# NM1330AE_v1 register map
File version: 1.0
Registers are 32-bit, read-write, reset 0x0 unless marked. A register's access mark holds for its fields unless they carry their own. Offsets are from the block's base; [hi:lo] are bit positions; {n}, {i} and the like mark numbered series.

## GCR — GCR Register Map
Base 0x50000000
0x00 PDID ro reset 0x10005200 — Part Device Identification Number Register
  [31:0] PDID — Part Device Identification Number. This register reflects the device part number code. Software can read this register to identify which device is used. For example, M052LBN PDID code is 0x1000_5200.
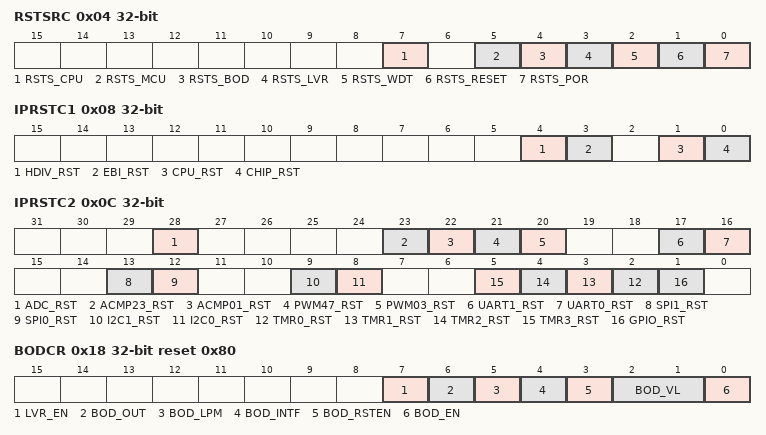
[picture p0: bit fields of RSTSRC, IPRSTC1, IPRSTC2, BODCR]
0x04 RSTSRC (reset mask 0xFFFFFF00) — System Reset Source Register
  [7] RSTS_CPU — CPU Reset Flag. The RSTS_CPU flag is set by hardware if software writes CPU_RST (IPRSTC1[1]) 1 to reset Cortex-M0 core and Flash memory controller (FMC). Note: Write 1 to clear this bit to 0.
    0=No reset from CPU; 1=Cortex-M0 core and FMC are reset by software setting CPU_RST to 1
  [5] RSTS_MCU — MCU Reset Flag. The RSTS_MCU flag is set by the "reset signal" from the Cortex-M0 core to indicate the previous reset source. Note: Write 1 to clear this bit to 0.
    0=No reset from Cortex-M0; 1=The Cortex-M0 had issued the reset signal to reset the system by writing 1 to bit SYSRESETREQ (AIRCR[2], Application Interrupt and Reset Control Register, address = 0xE000ED0C) in system control registers of Cortex-M0 core
  [4] RSTS_BOD — Brown-out Detector Reset Flag. The RSTS_BOD flag is set by the "reset signal" from the Brown-out Detector to indicate the previous reset source. Note: Write 1 to clear this bit to 0.
    0=No reset from BOD; 1=The BOD had issued the reset signal to reset the system
  [3] RSTS_LVR — Low Voltage Reset Flag. The RSTS_LVR flag is set by the "reset signal" from the Low-Voltage-Reset controller to indicate the previous reset source. Note: Write 1 to clear this bit to 0.
    0=No reset from LVR; 1=The LVR controller had issued the reset signal to reset the system
  [2] RSTS_WDT — Watchdog Reset Flag. The RSTS_WDT flag is set by the "reset signal" from the watchdog timer to indicate the previous reset source. Note: Write 1 to clear this bit to 0.
    0=No reset from watchdog timer; 1=The watchdog timer had issued the reset signal to reset the system
  [1] RSTS_RESET — Reset Pin Reset Flag. The RSTS_RESET flag is set by the "reset signal" from the nRST pin to indicate the previous reset source. Note: Write 1 to clear this bit to 0.
    0=No reset from the nRST pin; 1=The nRST pin had issued the reset signal to reset the system
  [0] RSTS_POR — Power-on Reset Flag. The RSTS_POR flag is set by the "reset signal" from the Power-on Reset (POR) controller or bit CHIP_RST (IPRSTC1[0]) to indicate the previous reset source. Note: Write 1 to clear this bit to 0.
    0=No reset from POR or CHIP_RST; 1=The Power-on Reset (POR) or CHIP_RST had issued the reset signal to reset the system
0x08 IPRSTC1 — Peripheral Reset Control Register 1
  [4] HDIV_RST — HDIV Controller Reset (Write Protect). Set this bit to 1 will generate a reset signal to the hardware divider. User need to set this bit to 0 to release from the reset state. Note: This bit is the protected bit, and programming it needs to write "59h", "16h", and "88h" to address 0x5000_0100 to disable register protection. Refer to the register REGWRPROT at address GCR_BA+0x100.
    0=Hardware divider controller normal operation; 1=Hardware divider controller reset
  [3] EBI_RST — EBI Controller Reset (Write Protect). Set this bit to 1 will generate a reset signal to the EBI. User needs to set this bit to 0 to release from the reset state. Note: This bit is the protected bit, and programming it needs to write "59h", "16h", and "88h" to address 0x5000_0100 to disable register protection. Refer to the register REGWRPROT at address GCR_BA+0x100.
    0=EBI controller normal operation; 1=EBI controller reset
  [1] CPU_RST — Cortext-M0 Core One-shot Reset (Write Protect). Setting this bit will only reset the Cortext-M0 core and Flash Memory Controller (FMC), and this bit will automatically return 0 after the two clock cycles. Note: This bit is the protected bit, and programming it needs to write "59h", "16h", and "88h" to address 0x5000_0100 to disable register protection. Refer to the register REGWRPROT at address GCR_BA+0x100.
    0=Cortext-M0 core normal operation; 1=Cortext-M0 core one-shot reset
  [0] CHIP_RST — Chip One-shot Reset (Write Protect). Setting this bit will reset the whole chip, including Cortext-M0 core and all peripherals, and this bit will automatically return to 0 after the 2 clock cycles. The CHIP_RST is the same as the POR reset. All the chip controllers are reset and the chip setting from CONFIG0 are also reload. Note: This bit is the protected bit, and programming it needs to write "59h", "16h", and "88h" to address 0x5000_0100 to disable register protection. Refer to the register REGWRPROT at address GCR_BA+0x100.
    0=Chip normal operation; 1=Chip one-shot reset
0x0C IPRSTC2 — Peripheral Reset Control Register 2
  [28] ADC_RST — ADC Controller Reset
    0=ADC controller normal operation; 1=ADC controller reset
  [23] ACMP23_RST — Analog Comparator B Controller Reset
    0=Analog Comparator B controller normal operation; 1=Analog Comparator B controller reset
  [22] ACMP01_RST — Analog Comparator A Controller Reset
    0=Analog Comparator A controller normal operation; 1=Analog Comparator A controller reset
  [21] PWM47_RST — PWM47 Controller Reset
    0=PWM47 controller normal operation; 1=PWM47 controller reset
  [20] PWM03_RST — PWM03 Controller Reset
    0=PWM03 controller normal operation; 1=PWM03 controller reset
  [17] UART1_RST — UART1 Controller Reset
    0=UART1 controller normal operation; 1=UART1 controller reset
  [16] UART0_RST — UART0 Controller Reset
    0=UART0 controller normal operation; 1=UART0 controller reset
  [13] SPI1_RST — SPI1 Controller Reset
    0=SPI1 controller normal operation; 1=SPI1 controller reset
  [12] SPI0_RST — SPI0 Controller Reset
    0=SPI0 controller normal operation; 1=SPI0 controller reset
  [9] I2C1_RST — I2C1 Controller Reset
    0=I2C1 controller normal operation; 1=I2C1 controller reset
  [8] I2C0_RST — I2C Controller Reset
    0=I2C0 controller normal operation; 1=I2C0 controller reset
  [n+2] TMR{n}_RST (n=0..3) — Timer{n} Controller Reset
    0=Timer{n} controller normal operation; 1=Timer{n} controller reset
  [1] GPIO_RST — GPIO (P0~P4) Controller Reset
    0=GPIO controller normal operation; 1=GPIO controller reset
0x18 BODCR reset 0x80 (reset mask 0xFFFFFFF0) — Brown-out Detector Control Register
  [7] LVR_EN — Low Voltage Reset Enable Control (Write Protect). The LVR function reset the chip when the input power voltage is lower than LVR circuit setting. LVR function is enabled by default. Note: This bit is the protected bit, and programming it needs to write "59h", "16h", and "88h" to address 0x5000_0100 to disable register protection. Refer to the register REGWRPROT at address GCR_BA+0x100.
    0=Low Voltage Reset function Disabled; 1=Low Voltage Reset function Enabled - After enabling the bit, the LVR function will be active with 100us delay for LVR output stable (default)
  [6] BOD_OUT — Brown-out Detector Output Status
    0=Brown-out Detector output status is 0, which means the detected voltage is higher than BOD_VL setting or BOD_EN is 0; 1=Brown-out Detector output status is 1, which means the detected voltage is lower than BOD_VL setting. If the BOD_EN is 0, BOD function disabled, this bit always responds to 0
  [5] BOD_LPM — Brown-out Detector Low power Mode (Write Protect). Note1: The BOD consumes about 100 uA in Normal mode, and the low power mode can reduce the current to about 1/10 but slow the BOD response. Note2: This bit is the protected bit, and programming it needs to write "59h", "16h", and "88h" to address 0x5000_0100 to disable register protection. Refer to the register REGWRPROT at address GCR_BA+0x100.
    0=BOD operated in Normal mode (default); 1=BOD Low Power mode Enabled
  [4] BOD_INTF — Brown-out Detector Interrupt Flag. Note: Write 1 to clear this bit to 0.
    0=Brown-out Detector does not detect any voltage draft at VDD down through or up through the voltage of BOD_VL setting; 1=When Brown-out Detector detects the VDD is dropped down through the voltage of BOD_VL setting or the VDD is raised up through the voltage of BOD_VL setting, this bit is set to 1 and the Brown-out interrupt is requested if Brown-out interrupt is enabled
  [3] BOD_RSTEN — Brown-out Reset Enable Control (Write Protect). Note1: While the Brown-out Detector function is enabled (BOD_EN high) and BOD reset function is enabled (BOD_RSTEN high), BOD will assert a signal to reset chip when the detected voltage is lower than the threshold (BOD_OUT high). Note2: The default value is set by flash controller user configuration register config0 bit[20]. Note3: This bit is the protected bit, and programming it needs to write "59h", "16h", and "88h" to address 0x5000_0100 to disable register protection. Refer to the register REGWRPROT at address GCR_BA+0x100.
    0=Brown-out "INTERRUPT" function Enabled; 1=Brown-out "RESET" function Enabled
  [2:1] BOD_VL — Brown-out Detector Threshold Voltage Select (Write Protect)
  [0] BOD_EN — Brown-out Detector Enable Control (Write Protect). The default value is set by flash controller user configuration register config0 bit[23]. Note: This bit is the protected bit, and programming it needs to write "59h", "16h", and "88h" to address 0x5000_0100 to disable register protection. Refer to the register REGWRPROT at address GCR_BA+0x100.
    0=Brown-out Detector function Disabled; 1=Brown-out Detector function Enabled
0x1C TEMPCR — Temperature Sensor Control Register
  [0] VTEMP_EN — Temperature Sensor Enable Control. This bit is used to enable/disable temperature sensor function. Note: After this bit is set to 1, the value of temperature sensor output can be obtained from the ADC conversion result. Please refer to the ADC chapter for detailed ADC conversion functional description.
    0=Temperature sensor function Disabled (default); 1=Temperature sensor function Enabled
0x24 PORCR (reset mask 0xFFFFFF00) — Power-on Reset Controller Register
  [15:0] POR_DIS_CODE — Power-on Reset Enable Control (Write Protect). When powered on, the POR circuit generates a reset signal to reset the whole chip function, but noise on the power may cause the POR active again. User can disable internal POR circuit to avoid unpredictable noise to cause chip reset by writing 0x5AA5 to this field. The POR function will be active again when this field is set to another value or chip is reset by other reset source, including: nRST, Watchdog reset, LVR reset, BOD reset, ICE reset command and the software-chip reset function. Note: This bit is the protected bit, and programming it needs to write "59h", "16h", and "88h" to address 0x5000_0100 to disable register protection. Refer to the register REGWRPROT at address GCR_BA+0x100.
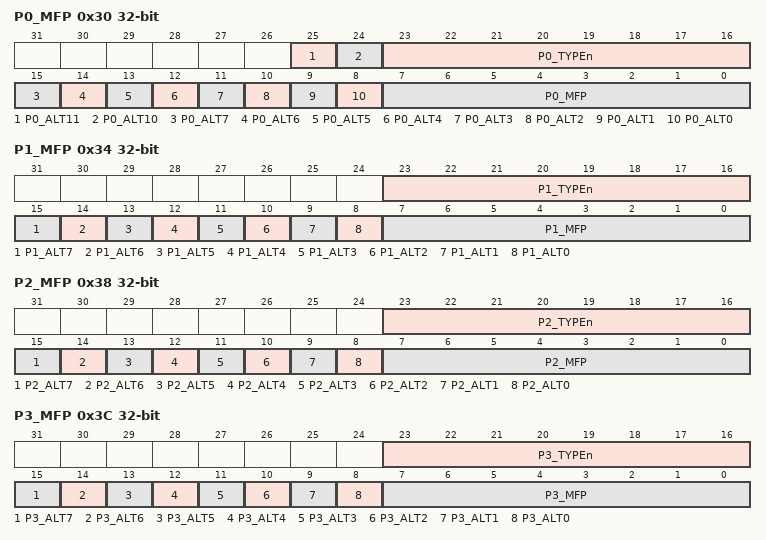
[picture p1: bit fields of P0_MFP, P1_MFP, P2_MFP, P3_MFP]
0x30 P0_MFP — P0 Multiple Function and Input Type Control Register
  [25] P0_ALT11 — P0.1 Alternate Function Selection1. The pin function of P0.1 depends on P0_MFP[1], P0_ALT[1], and P0_ALT1[1]. Refer to P0_ALT[1] for detailed description.
  [24] P0_ALT10 — P0.0 Alternate Function Selection1. The pin function of P0.0 depends on P0_MFP[0], P0_ALT[0], and P0_ALT1[0]. Refer to P0_ALT[0] for detailed description.
  [23:16] P0_TYPEn — P0[7:0] Input Schmitt Trigger Function Enable Control
    0=P0[7:0] I/O input Schmitt Trigger function Disabled; 1=P0[7:0] I/O input Schmitt Trigger function Enabled
  [15] P0_ALT7 — P0.7 Alternate Function Selection
  [14] P0_ALT6 — P0.6 Alternate Function Selection
  [13] P0_ALT5 — P0.5 Alternate Function Selection
  [12] P0_ALT4 — P0.4 Alternate Function Selection
  [11] P0_ALT3 — P0.3 Alternate Function Selection
  [10] P0_ALT2 — P0.2 Alternate Function Selection
  [9] P0_ALT1 — P0.1 Alternate Function Selection
  [8] P0_ALT0 — P0.0 Alternate Function Selection
  [7:0] P0_MFP — P0 Multiple Function Selection. The pin function of P0 depends on P0_MFP and P0_ALT. Refer to P0_ALT for detailed description.
0x34 P1_MFP — P1 Multiple Function and Input Type Control Register
  [23:16] P1_TYPEn — P1[7:0] Input Schmitt Trigger function Enable Control
    0=P1[7:0] I/O input Schmitt Trigger function Disabled; 1=P1[7:0] I/O input Schmitt Trigger function Enabled
  [15] P1_ALT7 — P1.7 Alternate Function Selection
  [14] P1_ALT6 — P1.6 Alternate Function Selection
  [13] P1_ALT5 — P1.5 Alternate Function Selection
  [12] P1_ALT4 — P1.4 Alternate Function Selection
  [11] P1_ALT3 — P1.3 Alternate Function Selection
  [10] P1_ALT2 — P1.2 Alternate Function Selection
  [9] P1_ALT1 — P1.1 Alternate Function Selection
  [8] P1_ALT0 — P1.0 Alternate Function Selection
  [7:0] P1_MFP — P1 Multiple Function Selection. The pin function of P1 depends on P1_MFP and P1_ALT. Refer to P1_ALT for detailed description.
0x38 P2_MFP — P2 Multiple Function and Input Type Control Register
  [23:16] P2_TYPEn — P2[7:0] Input Schmitt Trigger Function Enable Control
    0=P2[7:0] I/O input Schmitt Trigger function Disabled; 1=P2[7:0] I/O input Schmitt Trigger function Enabled
  [15] P2_ALT7 — P2.7 Alternate Function Selection
  [14] P2_ALT6 — P2.6 Alternate Function Selection
  [13] P2_ALT5 — P2.5 Alternate Function Selection
  [12] P2_ALT4 — P2.4 Alternate Function Selection
  [11] P2_ALT3 — P2.3 Alternate Function Selection
  [10] P2_ALT2 — P2.2 Alternate Function Selection
  [9] P2_ALT1 — P2.1 Alternate Function Selection
  [8] P2_ALT0 — P2.0 Alternate Function Selection
  [7:0] P2_MFP — P2 Multiple Function Selection. The pin function of P2 depends on P2_MFP and P2_ALT. Refer to P2_ALT for detailed description.
0x3C P3_MFP — P3 Multiple Function and Input Type Control Register
  [23:16] P3_TYPEn — P3[7:0] Input Schmitt Trigger function Enable
    0=P3[7:0] I/O input Schmitt Trigger function Disabled; 1=P3[7:0] I/O input Schmitt Trigger function Enabled
  [15] P3_ALT7 — P3.7 Alternate Function Selection
  [14] P3_ALT6 — P3.6 Alternate Function Selection
  [13] P3_ALT5 — P3.5 Alternate Function Selection
  [12] P3_ALT4 — P3.4 Alternate Function Selection
  [11] P3_ALT3 — P3.3 Alternate Function Selection
  [10] P3_ALT2 — P3.2 Alternate Function Selection
  [9] P3_ALT1 — P3.1 Alternate Function Selection
  [8] P3_ALT0 — P3.0 Alternate Function Selection
  [7:0] P3_MFP — P3 Multiple Function Selection. The pin function of P3 depends on P3_MFP and P3_ALT. Refer to P3_ALT for detailed description.
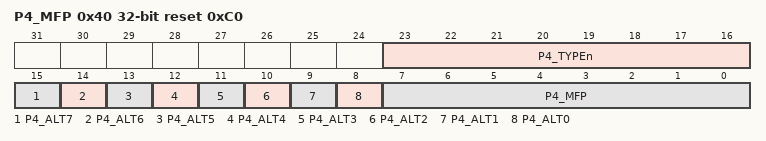
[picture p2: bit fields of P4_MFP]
0x40 P4_MFP reset 0xC0 — P4 Multiple Function and Input Type Control Register
  [23:16] P4_TYPEn — P4[7:0] Input Schmitt Trigger function Enable Control
    0=P4[7:0] I/O input Schmitt Trigger function Disabled; 1=P4[7:0] I/O input Schmitt Trigger function Enabled
  [15] P4_ALT7 — P4.7 Alternate Function Selection
  [14] P4_ALT6 — P4.6 Alternate Function Selection
  [13] P4_ALT5 — P4.5 Alternate Function Selection
  [12] P4_ALT4 — P4.4 Alternate Function Selection
  [11] P4_ALT3 — P4.3 Alternate Function Selection
  [10] P4_ALT2 — P4.2 Alternate Function Selection
  [9] P4_ALT1 — P4.1 Alternate Function Selection
  [8] P4_ALT0 — P4.0 Alternate Function Selection
  [7:0] P4_MFP — P4 Multiple Function Selection. The pin function of P4 depends on P4_MFP and P4_ALT. Refer to P4_ALT for detailed description.
0x100 REGWRPROT — Register Write-Protection Control Register
  [0] REGPROTDIS ro — Register Write-Protection Disable index (Read Only)
    0=Write-protection Enabled for writing protected registers. Any write to the protected register is ignored; 1=Write-protection Disabled for writing protected registers
  [7:0] REGWRPROT wo — Register Write-Protection Code (Write Only). Some registers have write-protection function. Writing these registers have to disable the protected function by writing the sequence value "59h", "16h", "88h" to this field. After this sequence is completed, the REGPROTDIS bit will be set to 1 and write-protection registers can be normal write.
